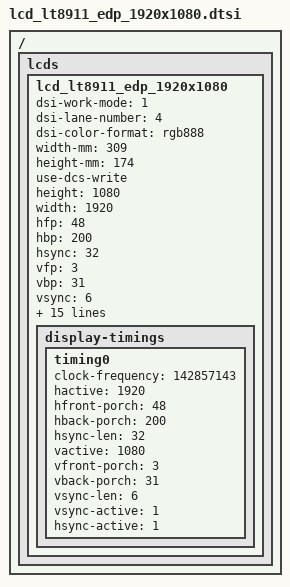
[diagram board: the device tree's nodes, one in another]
// SPDX-License-Identifier: GPL-2.0

/ { lcds: lcds {
	lcd_lt8911_edp_1920x1080: lcd_lt8911_edp_1920x1080 {
		dsi-work-mode = <1>; /* video burst mode*/
		dsi-lane-number = <4>;
		dsi-color-format = "rgb888";
		width-mm = <309>;
		height-mm = <174>;
		use-dcs-write;

		/*mipi info*/
		height = <1080>;
		width = <1920>;
		hfp = <48>;
		hbp = <200>;
		hsync = <32>;
		vfp = <3>;
		vbp = <31>;
		vsync = <6>;
		fps = <60>;
		work-mode = <0>;
		rgb-mode = <3>;
		lane-number = <4>;
		phy-bit-clock = <933000000>;
		split-enable = <0>;
		eotp-enable = <1>;
		burst-mode = <2>;
		esd-check-enable = <0>;

		/* DSI_CMD, DSI_MODE, timeout, len, cmd */
		initial-command = [
			39 01 F0 01 11
			39 01 28 01 29
		];
		sleep-in-command = [
			39 01 78 01 28
			39 01 78 01 10
		];
		sleep-out-command = [
			39 01 96 01 11
			39 01 32 01 29
		];

		display-timings {
			timing0 {
				clock-frequency = <142857143>;
				hactive = <1920>;
				hfront-porch = <48>;
				hback-porch = <200>;
				hsync-len = <32>;
				vactive = <1080>;
				vfront-porch = <3>;
				vback-porch = <31>;
				vsync-len = <6>;
				vsync-active = <1>;
				hsync-active = <1>;
			};
		};
	};
};};
